# SMS0_WDTCTRL_1_HSM_CTRL_MMR register map
Vendor: Texas Instruments
Peripheral module from a debugger description file (folder am62P).
Registers are 32-bit, read-write, reset 0x0 unless marked. A register's access mark holds for its fields unless they carry their own. Offsets are as the file gives them; lines under a group give offsets from that group; [hi:lo] are bit positions; {n}, {i} and the like mark numbered series; 'fields as' and 'values as' point back to an identical list; <NAME> marks a mode.

## SMS0_WDTCTRL_1_HSM_CTRL_MMR
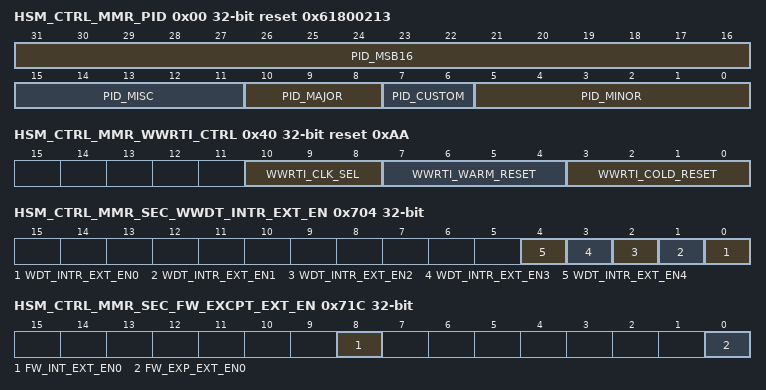
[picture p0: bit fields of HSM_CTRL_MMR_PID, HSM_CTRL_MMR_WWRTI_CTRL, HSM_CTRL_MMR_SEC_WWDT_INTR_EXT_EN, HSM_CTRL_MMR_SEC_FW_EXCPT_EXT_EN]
0x00 HSM_CTRL_MMR_PID ro reset 0x61800213
  [31:16] PID_MSB16, [15:11] PID_MISC, [10:8] PID_MAJOR, [7:6] PID_CUSTOM, [5:0] PID_MINOR
0x20 HSM_CTRL_MMR_LOCK0_KICK0
  [31:0] LOCK0_KICK0 — - KICK0 component
0x24 HSM_CTRL_MMR_LOCK0_KICK1
  [31:0] LOCK0_KICK1 — - KICK1 component
0x40 HSM_CTRL_MMR_WWRTI_CTRL reset 0xAA
  [10:8] WWRTI_CLK_SEL, [7:4] WWRTI_WARM_RESET, [3:0] WWRTI_COLD_RESET
0x50 HSM_CTRL_MMR_WWRTI_CLOCK_CTRL reset 0xA
  [3:0] WWRTI_CLK_CTRL
0x704 HSM_CTRL_MMR_SEC_WWDT_INTR_EXT_EN
  [n] WDT_INTR_EXT_EN{n} (n=0..4)
0x70C HSM_CTRL_MMR_SEC_ECC_AGGR_INTR_EXT_EN
  [0] ECC_AGGR_INTR_EXT_EN0
0x71C HSM_CTRL_MMR_SEC_FW_EXCPT_EXT_EN
  [8] FW_INT_EXT_EN0, [0] FW_EXP_EXT_EN0
0x724 HSM_CTRL_MMR_SEC_RAT_INTR_EXT_EN
  [0] RAT_INTR_EXT_EN
0x800 HSM_CTRL_MMR_SEC_HSM_RESET
  [1] RESET_MASK
